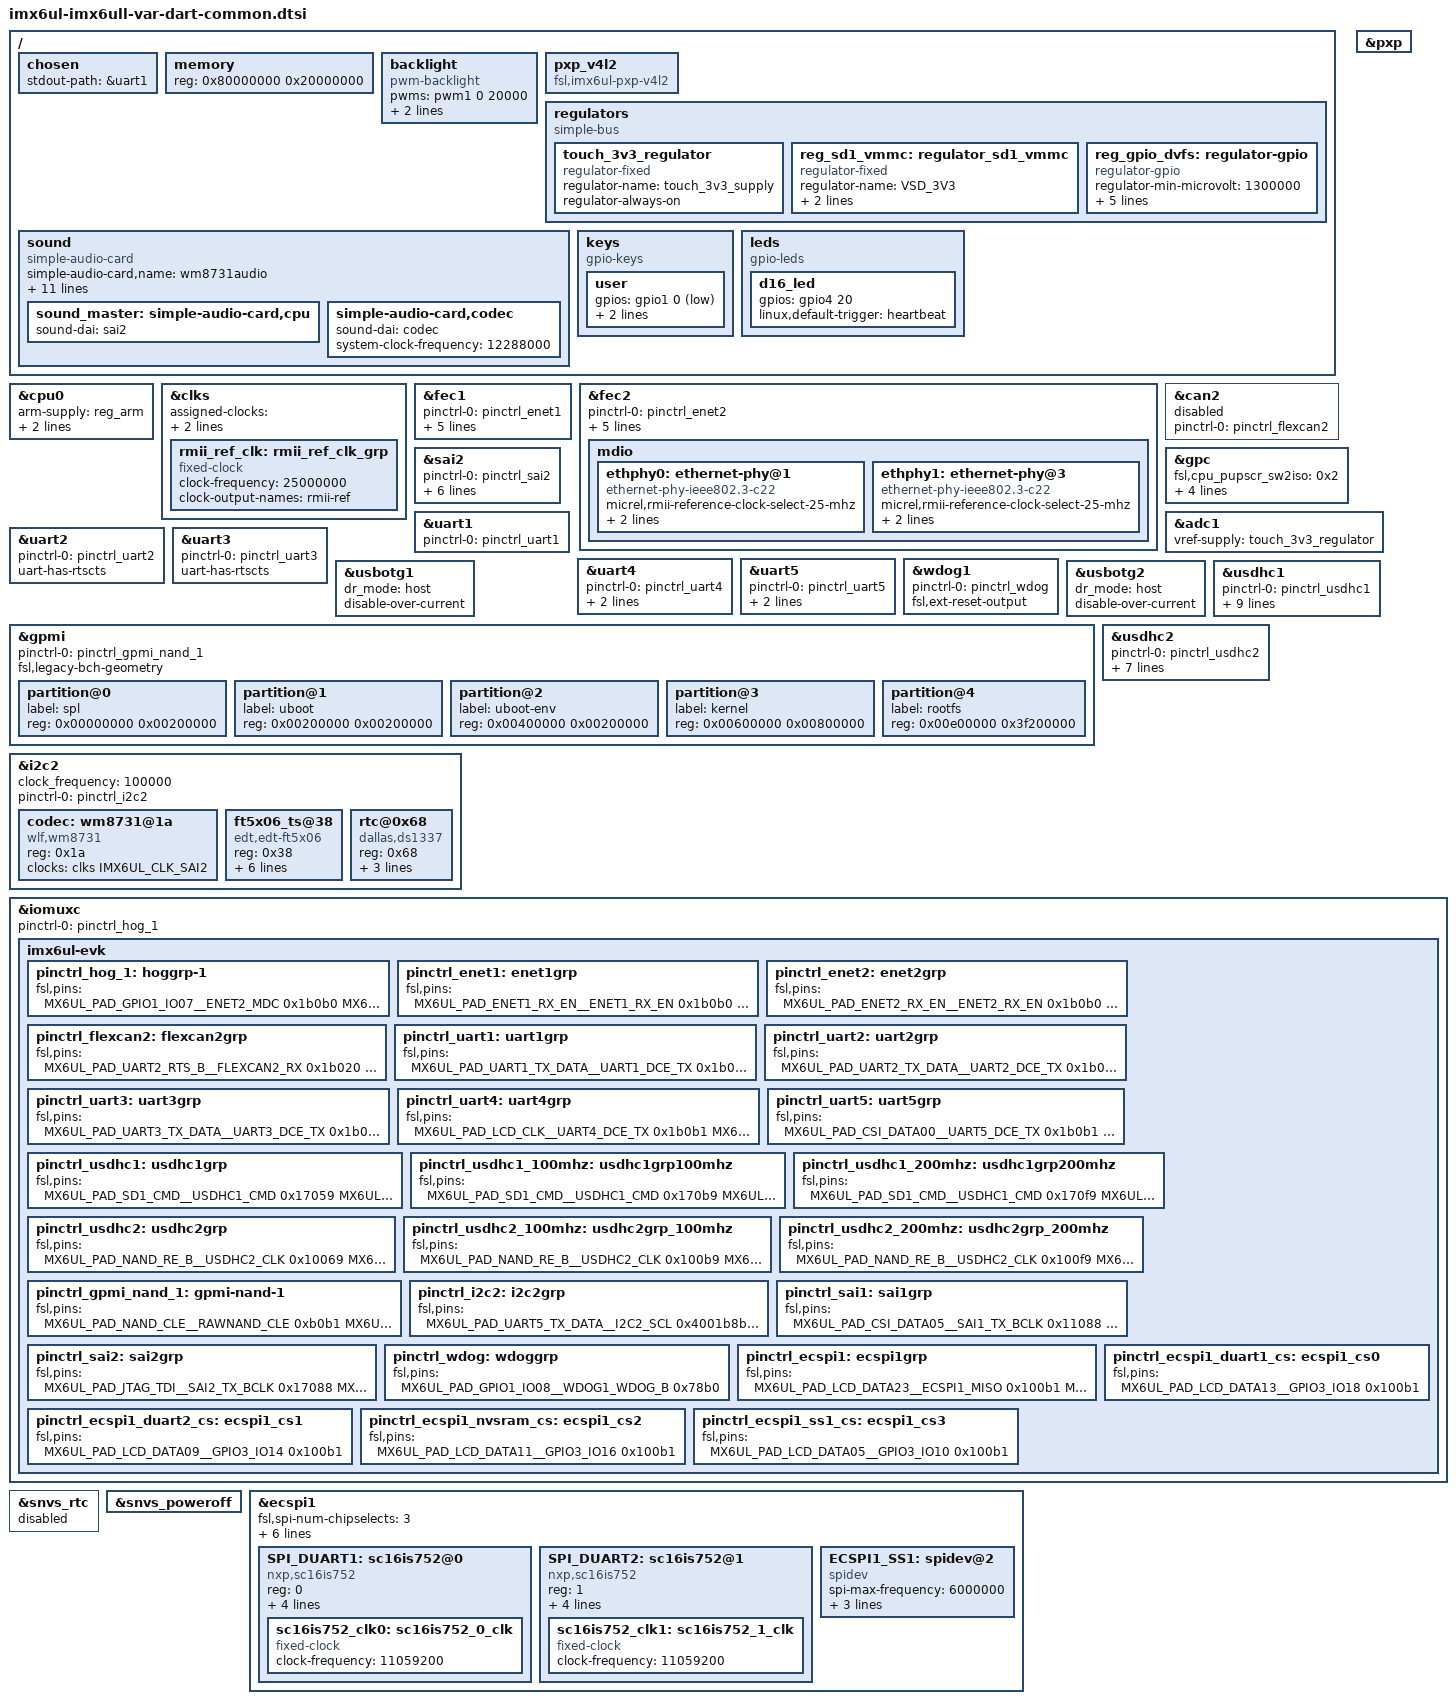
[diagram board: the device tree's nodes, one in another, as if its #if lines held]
/*
 * Copyright (C) 2015 Freescale Semiconductor, Inc.
 *
 * Copyright (C) 2015-2017 Variscite Ltd. - http://www.variscite.com
 *
 * This program is free software; you can redistribute it and/or modify
 * it under the terms of the GNU General Public License version 2 as
 * published by the Free Software Foundation.
 */
/* #define WIFI */
/* #define EMMC */
/* #define  NAND  */

/ {
	chosen {
		stdout-path = &uart1;
	};

	memory {
		reg = <0x80000000 0x20000000>;
	};

	backlight {
		compatible = "pwm-backlight";
		pwms = <&pwm1 0 20000>;
		brightness-levels = <0 4 8 16 32 64 128 255>;
		default-brightness-level = <6>;
		status = "okay";
	};

	pxp_v4l2 {
		compatible = "fsl,imx6ul-pxp-v4l2", "fsl,imx6sx-pxp-v4l2", "fsl,imx6sl-pxp-v4l2";
		status = "okay";
	};

	regulators {
		compatible = "simple-bus";
		#address-cells = <1>;
		#size-cells = <0>;

		touch_3v3_regulator: touch_3v3_regulator {
			compatible = "regulator-fixed";
			regulator-name = "touch_3v3_supply";
			regulator-always-on;
			status = "okay";
		};

#ifdef WIFI
		reg_sd1_vmmc: regulator_sd1_vmmc {
			compatible = "regulator-fixed";
			regulator-name = "VSD_3V3";
			regulator-min-microvolt = <3300000>;
			regulator-max-microvolt = <3300000>;
		};
#endif
		reg_gpio_dvfs: regulator-gpio {
			compatible = "regulator-gpio";
			regulator-min-microvolt = <1300000>;
			regulator-max-microvolt = <1400000>;
			regulator-name = "gpio_dvfs";
			regulator-type = "voltage";
			gpios = <&gpio4 13 GPIO_ACTIVE_HIGH>;
			states = <1300000 0x1 1400000 0x0>;
		};
	};

	sound {
		compatible = "simple-audio-card";
		simple-audio-card,name = "wm8731audio";
		simple-audio-card,widgets =
			"Headphone", "Headphone Jack",
			"Line", "Line Jack",
			"Microphone", "Mic Jack";
		simple-audio-card,routing =
			"Headphone Jack", "RHPOUT",
			"Headphone Jack", "LHPOUT",
			"LLINEIN", "Line Jack",
			"RLINEIN", "Line Jack",
			"MICIN", "Mic Bias",
			"Mic Bias", "Mic Jack";
		simple-audio-card,format = "i2s";
		simple-audio-card,bitclock-master = <&sound_master>;
		simple-audio-card,frame-master = <&sound_master>;
		/*simple-audio-card,bitclock-inversion;*/

		sound_master: simple-audio-card,cpu {
			sound-dai = <&sai2>;
		};

		simple-audio-card,codec {
			sound-dai = <&codec>;
			system-clock-frequency = <12288000>;
		};
	};

	keys {
		compatible = "gpio-keys";

		user {
			gpios = <&gpio1 0 GPIO_ACTIVE_LOW>;
			linux,code = <KEY_BACK>;
			gpio-key,wakeup;
		};
	};

	leds {
		compatible = "gpio-leds";

		d16_led {
			gpios = <&gpio4 20 0>;
			linux,default-trigger = "heartbeat";
		};
	};
};

&cpu0 {
	arm-supply = <&reg_arm>;
	soc-supply = <&reg_soc>;
	dc-supply = <&reg_gpio_dvfs>;
};

&clks {
	/* ref_clk for micrel ethernet phy */
	rmii_ref_clk: rmii_ref_clk_grp {
		compatible = "fixed-clock";
		#clock-cells = <0>;
		clock-frequency = <25000000>;
		clock-output-names = "rmii-ref";
	};
};

&clks {
	assigned-clocks = <&clks IMX6UL_CLK_PLL4_AUDIO_DIV>;
	assigned-clock-rates = <786432000>;
};

&fec1 {
	pinctrl-names = "default";
	pinctrl-0 = <&pinctrl_enet1>;
	phy-mode = "rmii";
	phy-reset-gpios=<&gpio5 0 1>;
	phy-reset-duration=<100>;
	phy-reset-on-resume;
	phy-handle = <&ethphy0>;
	status = "okay";
};

&fec2 {
	pinctrl-names = "default";
	pinctrl-0 = <&pinctrl_enet2>;
	phy-mode = "rmii";
	phy-handle = <&ethphy1>;
	phy-reset-gpios=<&gpio1 10 1>;
	phy-reset-duration=<100>;
	phy-reset-on-resume;
	status = "okay";
	mdio {
		#address-cells = <1>;
		#size-cells = <0>;

		ethphy0: ethernet-phy@1 {
			compatible = "ethernet-phy-ieee802.3-c22";
			micrel,rmii-reference-clock-select-25-mhz;
			clocks = <&rmii_ref_clk>;
			clock-names = "rmii-ref";
			reg = <1>;
		};

		ethphy1: ethernet-phy@3 {
			compatible = "ethernet-phy-ieee802.3-c22";
			micrel,rmii-reference-clock-select-25-mhz;
			clocks = <&rmii_ref_clk>;
			clock-names = "rmii-ref";
			reg = <3>;
		};
	};
};

&can2 {
	pinctrl-names = "default";
	pinctrl-0 = <&pinctrl_flexcan2>;
	status = "disabled";
};

&gpc {
	fsl,cpu_pupscr_sw2iso = <0x2>;
	fsl,cpu_pupscr_sw = <0x1>;
	fsl,cpu_pdnscr_iso2sw = <0x1>;
	fsl,cpu_pdnscr_iso = <0x1>;
	fsl,ldo-bypass = <0>; /* DCDC, ldo-enable */
};

&pxp {
	status = "okay";
};

&sai2 {
	pinctrl-names = "default";
	pinctrl-0 = <&pinctrl_sai2>;
	assigned-clocks = <&clks IMX6UL_CLK_SAI2_SEL>,
			  <&clks IMX6UL_CLK_SAI2>;
	assigned-clock-parents = <&clks IMX6UL_CLK_PLL4_AUDIO_DIV>;
	assigned-clock-rates = <0>, <12288000>;
	fsl,sai-mclk-direction-output;
	status = "okay";
};

&adc1 {
	vref-supply = <&touch_3v3_regulator>;
	status = "okay";
};

/* Console UART */
&uart1 {
	pinctrl-names = "default";
	pinctrl-0 = <&pinctrl_uart1>;
	status = "okay";
};

/* Bluetooth UART */
&uart2 {
	pinctrl-names = "default";
	pinctrl-0 = <&pinctrl_uart2>;
	uart-has-rtscts;
	status = "okay";
};

/* ttymxc2 UART */
&uart3 {
	pinctrl-names = "default";
	pinctrl-0 = <&pinctrl_uart3>;
	uart-has-rtscts;
	status = "okay";
};

/* ttymxc3 UART */
&uart4 {
	pinctrl-names = "default";
	pinctrl-0 = <&pinctrl_uart4>;
	dcd-gpios = <&gpio1 5 GPIO_ACTIVE_LOW>;
	fsl,uart-has-rtscts;
	status = "okay";
};

/* ttymxc4 UART */
&uart5 {
	pinctrl-names = "default";
	pinctrl-0 = <&pinctrl_uart5>;
	dcd-gpios = <&gpio5 1 GPIO_ACTIVE_LOW>;
	fsl,uart-has-rtscts;
	status = "okay";
};

&wdog1 {
	pinctrl-names = "default";
	pinctrl-0 = <&pinctrl_wdog>;
	fsl,ext-reset-output;
};

&usbotg1 {
	dr_mode = "host";
	disable-over-current;
	status = "okay";
};

&usbotg2 {
	dr_mode = "host";
	disable-over-current;
	status = "okay";
};

#ifdef WIFI
#ifdef WIFI_5G
/*  Wi-Fi/BT SD Card Slot Definition */
&usdhc1 {
	pinctrl-names = "default", "state_100mhz", "state_200mhz";
	pinctrl-0 = <&pinctrl_usdhc1>;
	pinctrl-1 = <&pinctrl_usdhc1_100mhz>;
	pinctrl-2 = <&pinctrl_usdhc1_200mhz>;
	assigned-clocks = <&clks IMX6UL_CLK_USDHC1_SEL>, <&clks IMX6UL_CLK_USDHC1>;
	assigned-clock-parents = <&clks IMX6UL_CLK_PLL2_PFD2>;
	assigned-clock-rates = <0>, <132000000>;
	fsl,tuning-step= <2>;
	vmmc-supply = <&reg_sd1_vmmc>;
	status = "okay";
};
#else
&usdhc1 {
	pinctrl-names = "default", "state_100mhz", "state_200mhz";
	pinctrl-0 = <&pinctrl_usdhc1>;
	pinctrl-1 = <&pinctrl_usdhc1_100mhz>;
	pinctrl-2 = <&pinctrl_usdhc1_200mhz>;
	no-1-8-v;
	keep-power-in-suspend;
	vmmc-supply = <&reg_sd1_vmmc>;
	non-removable;
	status = "okay";
};
#endif /* WIFI_5G */
#else
&usdhc1 {
	pinctrl-names = "default", "state_100mhz", "state_200mhz";
	pinctrl-0 = <&pinctrl_usdhc1>;
	pinctrl-1 = <&pinctrl_usdhc1_100mhz>;
	pinctrl-2 = <&pinctrl_usdhc1_200mhz>;
	no-1-8-v;
	keep-power-in-suspend;
	enable-sdio-wakeup;
	cd-gpios = <&gpio4 19 GPIO_ACTIVE_LOW>;
	status = "okay";
};
#endif

#ifdef NAND
&gpmi {
	pinctrl-names = "default";
	pinctrl-0 = <&pinctrl_gpmi_nand_1>;
	fsl,legacy-bch-geometry;
	status = "okay";

	partition@0 {
		label = "spl";
		reg = <0x00000000 0x00200000>;
	};

	partition@1 {
		label = "uboot";
		reg = <0x00200000 0x00200000>;
	};

	partition@2 {
		label = "uboot-env";
		reg = <0x00400000 0x00200000>;
	};

	partition@3 {
		label = "kernel";
		reg = <0x00600000 0x00800000>;
	};

	partition@4 {
		label = "rootfs";
		reg = <0x00e00000 0x3f200000>;
	};
};

&usdhc2 {
	status = "disabled";
};
#endif

#ifdef EMMC
&usdhc2 {
	pinctrl-names = "default", "state_100mhz", "state_200mhz";
	pinctrl-0 = <&pinctrl_usdhc2>;
	pinctrl-1 = <&pinctrl_usdhc2_100mhz>;
	pinctrl-2 = <&pinctrl_usdhc2_200mhz>;
	bus-width = <8>;
	no-1-8-v;
	non-removable;
	keep-power-in-suspend;
	enable-sdio-wakeup;
	status = "okay";
};
#endif

&i2c2 {
	clock_frequency = <100000>;
	pinctrl-names = "default";
	pinctrl-0 = <&pinctrl_i2c2>;
	status = "okay";

	codec: wm8731@1a {
		#sound-dai-cells = <0>;
		compatible = "wlf,wm8731";
		reg = <0x1a>;
		clocks = <&clks IMX6UL_CLK_SAI2>;
		clock-names = "mclk";
	};

	ft5x06_ts@38 {
		compatible = "edt,edt-ft5x06";
		reg = <0x38>;
		interrupt-parent = <&gpio3>;
		interrupts = <4 0>;
		touchscreen-size-x = <800>;
		touchscreen-size-y = <480>;
		touchscreen-inverted-x;
		touchscreen-inverted-y;
	};

	/* DS1337 RTC module */
	rtc@0x68 {
		compatible = "dallas,ds1337";
		reg = <0x68>;
		pinctrl-names = "default";
		pinctrl-0 = <&pinctrl_rtc>;
		interrupt-parent = <&gpio5>;
		interrupts = <7 IRQ_TYPE_EDGE_FALLING>;
	};
};

&iomuxc {
	pinctrl-names = "default";
	pinctrl-0 = <&pinctrl_hog_1>;
	imx6ul-evk {
		pinctrl_hog_1: hoggrp-1 {
			fsl,pins = <
				MX6UL_PAD_GPIO1_IO07__ENET2_MDC		0x1b0b0
				MX6UL_PAD_GPIO1_IO06__ENET2_MDIO	0x1b0b0
#ifdef WIFI
				MX6UL_PAD_GPIO1_IO03__REF_CLK_32K	0x03029	/* WLAN Slow Clock */
#endif
				/* gpios */
				MX6UL_PAD_SNVS_TAMPER5__GPIO5_IO05	0x5800A0 /* SCC_AB */
				MX6UL_PAD_SNVS_TAMPER3__GPIO5_IO03	0x5800A0 /* SCC_DC */
				MX6UL_PAD_LCD_DATA02__GPIO3_IO07	0x5800A0 /* SCC_CE */
				MX6UL_PAD_LCD_DATA16__GPIO3_IO21	0x5800A0 /* SCC_D4 */
				MX6UL_PAD_LCD_DATA18__GPIO3_IO23	0x5800A0 /* SCC_D6 */
				MX6UL_PAD_LCD_DATA17__GPIO3_IO22	0x5800A0 /* SCC_D5 */
				MX6UL_PAD_LCD_DATA14__GPIO3_IO19	0x5800A0 /* SCC_D2 */
				MX6UL_PAD_LCD_DATA12__GPIO3_IO17	0x5800A0 /* SCC_D1 */
				MX6UL_PAD_LCD_DATA08__GPIO3_IO13	0x5800A0 /* SCC_D0 */
				MX6UL_PAD_LCD_DATA04__GPIO3_IO09	0x5800A0 /* GPS_RESET */
				MX6UL_PAD_LCD_DATA19__GPIO3_IO24	0x5800A0 /* SCC_D7 */
				MX6UL_PAD_LCD_DATA15__GPIO3_IO20	0x5800A0 /* SCC_D3 */
				MX6UL_PAD_LCD_DATA01__GPIO3_IO06	0x5800A0 /* SCC_RD */
				MX6UL_PAD_LCD_DATA03__GPIO3_IO08	0x5800A0 /* SCC_WR */
				MX6UL_PAD_LCD_DATA00__GPIO3_IO05	0x5800A0 /* SCC_INTACK */
				MX6UL_PAD_LCD_DATA10__GPIO3_IO15	0x5800A0 /* SCC_DIR */
				MX6UL_PAD_LCD_RESET__GPIO3_IO04		0x5800A0 /* SCC_IEO */
				MX6UL_PAD_CSI_PIXCLK__GPIO4_IO18	0x5800A0 /* HOST_USB_PWR_SW */
				MX6UL_PAD_CSI_MCLK__GPIO4_IO17		0x5800A0 /* HOST_USB_OVCR */
				MX6UL_PAD_GPIO1_IO05__GPIO1_IO05	0x5800A0 /* SP1_DCD */
				MX6UL_PAD_SNVS_TAMPER7__GPIO5_IO07	0x5800A0 /* RTC_IRQ */
				MX6UL_PAD_SNVS_TAMPER8__GPIO5_IO08	0x5800A0 /* HOST_LINESYNC */
				MX6UL_PAD_SNVS_TAMPER9__GPIO5_IO09	0x5800A0 /* PCA9555_INT */
				MX6UL_PAD_UART4_TX_DATA__GPIO1_IO28	0x5800A0 /* SCC_INT */
				MX6UL_PAD_GPIO1_IO01__GPIO1_IO01	0x5800A0 /* ENGX_USB_OVRC */
				MX6UL_PAD_GPIO1_IO02__GPIO1_IO02	0x5800A0 /* SPI_DUART_RESET */
				MX6UL_PAD_GPIO1_IO04__GPIO1_IO04	0x5800A0 /* ENGX_USB_VBUSCTRL */
				MX6UL_PAD_GPIO1_IO00__GPIO1_IO00	0x5800A0 /* ADC0.0 */
				MX6UL_PAD_SNVS_TAMPER1__GPIO5_IO01	0x5800A0 /* SP2_DCD */
			>;
		};

		pinctrl_enet1: enet1grp {
			fsl,pins = <
				MX6UL_PAD_ENET1_RX_EN__ENET1_RX_EN	0x1b0b0
				MX6UL_PAD_ENET1_RX_ER__ENET1_RX_ER	0x1b0b0
				MX6UL_PAD_ENET1_RX_DATA0__ENET1_RDATA00	0x1b0b0
				MX6UL_PAD_ENET1_RX_DATA1__ENET1_RDATA01	0x1b0b0
				MX6UL_PAD_ENET1_TX_EN__ENET1_TX_EN	0x1b0b0
				MX6UL_PAD_ENET1_TX_DATA0__ENET1_TDATA00	0x1b0b0
				MX6UL_PAD_ENET1_TX_DATA1__ENET1_TDATA01	0x1b0b0
				MX6UL_PAD_ENET1_TX_CLK__ENET1_REF_CLK1	0x4001b031
			>;
		};

		pinctrl_enet2: enet2grp {
			fsl,pins = <
				MX6UL_PAD_ENET2_RX_EN__ENET2_RX_EN	0x1b0b0
				MX6UL_PAD_ENET2_RX_ER__ENET2_RX_ER	0x1b0b0
				MX6UL_PAD_ENET2_RX_DATA0__ENET2_RDATA00	0x1b0b0
				MX6UL_PAD_ENET2_RX_DATA1__ENET2_RDATA01	0x1b0b0
				MX6UL_PAD_ENET2_TX_EN__ENET2_TX_EN	0x1b0b0
				MX6UL_PAD_ENET2_TX_DATA0__ENET2_TDATA00	0x1b0b0
				MX6UL_PAD_ENET2_TX_DATA1__ENET2_TDATA01	0x1b0b0
				MX6UL_PAD_ENET2_TX_CLK__ENET2_REF_CLK2	0x4001b031
				MX6UL_PAD_JTAG_MOD__GPIO1_IO10		0x1b0b0
			>;
		};

		pinctrl_flexcan2: flexcan2grp{
			fsl,pins = <
				MX6UL_PAD_UART2_RTS_B__FLEXCAN2_RX	0x1b020
				MX6UL_PAD_UART2_CTS_B__FLEXCAN2_TX	0x1b020
			>;
		};

		pinctrl_uart1: uart1grp {
			fsl,pins = <
				MX6UL_PAD_UART1_TX_DATA__UART1_DCE_TX	0x1b0b1
				MX6UL_PAD_UART1_RX_DATA__UART1_DCE_RX	0x1b0b1
			>;
		};

		pinctrl_uart2: uart2grp {
			fsl,pins = <
				MX6UL_PAD_UART2_TX_DATA__UART2_DCE_TX	0x1b0b1
				MX6UL_PAD_UART2_RX_DATA__UART2_DCE_RX	0x1b0b1
				MX6UL_PAD_UART2_CTS_B__UART2_DCE_CTS	0x1b0b1
				MX6UL_PAD_UART2_RTS_B__UART2_DCE_RTS	0x1b0b1
			>;
		};

		pinctrl_uart3: uart3grp {
			fsl,pins = <
				MX6UL_PAD_UART3_TX_DATA__UART3_DCE_TX	0x1b0b1
				MX6UL_PAD_UART3_RX_DATA__UART3_DCE_RX	0x1b0b1
				MX6UL_PAD_UART3_CTS_B__UART3_DCE_CTS	0x1b0b1
				MX6UL_PAD_UART3_RTS_B__UART3_DCE_RTS	0x1b0b1
			>;
		};

		pinctrl_uart4: uart4grp {
			fsl,pins = <
				MX6UL_PAD_LCD_CLK__UART4_DCE_TX		0x1b0b1
				MX6UL_PAD_LCD_ENABLE__UART4_DCE_RX	0x1b0b1
				MX6UL_PAD_LCD_VSYNC__UART4_DCE_RTS	0x1b0b1
				MX6UL_PAD_LCD_HSYNC__UART4_DCE_CTS	0x1b0b1
			>;
		};

		pinctrl_uart5: uart5grp {
			fsl,pins = <
				MX6UL_PAD_CSI_DATA00__UART5_DCE_TX	0x1b0b1
				MX6UL_PAD_CSI_DATA01__UART5_DCE_RX	0x1b0b1
				MX6UL_PAD_CSI_DATA03__UART5_DCE_CTS	0x1b0b1
				MX6UL_PAD_CSI_DATA02__UART5_DCE_RTS	0x1b0b1
			>;
		};

		pinctrl_usdhc1: usdhc1grp {
			fsl,pins = <
				MX6UL_PAD_SD1_CMD__USDHC1_CMD		0x17059
				MX6UL_PAD_SD1_CLK__USDHC1_CLK		0x17059
				MX6UL_PAD_SD1_DATA0__USDHC1_DATA0	0x17059
				MX6UL_PAD_SD1_DATA1__USDHC1_DATA1	0x17059
				MX6UL_PAD_SD1_DATA2__USDHC1_DATA2	0x17059
				MX6UL_PAD_SD1_DATA3__USDHC1_DATA3	0x17059
				MX6UL_PAD_CSI_VSYNC__GPIO4_IO19		0x1b0b1	/* SD card detect */
			>;
		};

		pinctrl_usdhc1_100mhz: usdhc1grp100mhz {
			fsl,pins = <
				MX6UL_PAD_SD1_CMD__USDHC1_CMD		0x170b9
				MX6UL_PAD_SD1_CLK__USDHC1_CLK		0x100b9
				MX6UL_PAD_SD1_DATA0__USDHC1_DATA0	0x170b9
				MX6UL_PAD_SD1_DATA1__USDHC1_DATA1	0x170b9
				MX6UL_PAD_SD1_DATA2__USDHC1_DATA2	0x170b9
				MX6UL_PAD_SD1_DATA3__USDHC1_DATA3	0x170b9
				MX6UL_PAD_CSI_VSYNC__GPIO4_IO19		0x1b0b1	/* SD card detect */
			>;
		};

		pinctrl_usdhc1_200mhz: usdhc1grp200mhz {
			fsl,pins = <
				MX6UL_PAD_SD1_CMD__USDHC1_CMD		0x170f9
				MX6UL_PAD_SD1_CLK__USDHC1_CLK		0x100f9
				MX6UL_PAD_SD1_DATA0__USDHC1_DATA0	0x170f9
				MX6UL_PAD_SD1_DATA1__USDHC1_DATA1	0x170f9
				MX6UL_PAD_SD1_DATA2__USDHC1_DATA2	0x170f9
				MX6UL_PAD_SD1_DATA3__USDHC1_DATA3	0x170f9
				MX6UL_PAD_CSI_VSYNC__GPIO4_IO19		0x1b0b1	/* SD card detect */
			>;
		};
#ifdef EMMC
		pinctrl_usdhc2: usdhc2grp {
			fsl,pins = <
				MX6UL_PAD_NAND_RE_B__USDHC2_CLK		0x10069
				MX6UL_PAD_NAND_WE_B__USDHC2_CMD		0x17059
				MX6UL_PAD_NAND_DATA00__USDHC2_DATA0	0x17059
				MX6UL_PAD_NAND_DATA01__USDHC2_DATA1	0x17059
				MX6UL_PAD_NAND_DATA02__USDHC2_DATA2	0x17059
				MX6UL_PAD_NAND_DATA03__USDHC2_DATA3	0x17059
				MX6UL_PAD_NAND_DATA04__USDHC2_DATA4	0x17059
				MX6UL_PAD_NAND_DATA05__USDHC2_DATA5	0x17059
				MX6UL_PAD_NAND_DATA06__USDHC2_DATA6	0x17059
				MX6UL_PAD_NAND_DATA07__USDHC2_DATA7	0x17059
			>;
		};

		pinctrl_usdhc2_100mhz: usdhc2grp_100mhz {
			fsl,pins = <
				MX6UL_PAD_NAND_RE_B__USDHC2_CLK		0x100b9
				MX6UL_PAD_NAND_WE_B__USDHC2_CMD		0x170b9
				MX6UL_PAD_NAND_DATA00__USDHC2_DATA0	0x170b9
				MX6UL_PAD_NAND_DATA01__USDHC2_DATA1	0x170b9
				MX6UL_PAD_NAND_DATA02__USDHC2_DATA2	0x170b9
				MX6UL_PAD_NAND_DATA03__USDHC2_DATA3	0x170b9
				MX6UL_PAD_NAND_DATA04__USDHC2_DATA4	0x170b9
				MX6UL_PAD_NAND_DATA05__USDHC2_DATA5	0x170b9
				MX6UL_PAD_NAND_DATA06__USDHC2_DATA6	0x170b9
				MX6UL_PAD_NAND_DATA07__USDHC2_DATA7	0x170b9
			>;
		};

		pinctrl_usdhc2_200mhz: usdhc2grp_200mhz {
			fsl,pins = <
				MX6UL_PAD_NAND_RE_B__USDHC2_CLK		0x100f9
				MX6UL_PAD_NAND_WE_B__USDHC2_CMD		0x170f9
				MX6UL_PAD_NAND_DATA00__USDHC2_DATA0	0x170f9
				MX6UL_PAD_NAND_DATA01__USDHC2_DATA1	0x170f9
				MX6UL_PAD_NAND_DATA02__USDHC2_DATA2	0x170f9
				MX6UL_PAD_NAND_DATA03__USDHC2_DATA3	0x170f9
				MX6UL_PAD_NAND_DATA04__USDHC2_DATA4	0x170f9
				MX6UL_PAD_NAND_DATA05__USDHC2_DATA5	0x170f9
				MX6UL_PAD_NAND_DATA06__USDHC2_DATA6	0x170f9
				MX6UL_PAD_NAND_DATA07__USDHC2_DATA7	0x170f9
			>;
		};
#endif
#ifdef NAND
		pinctrl_gpmi_nand_1: gpmi-nand-1 {
			fsl,pins = <
				MX6UL_PAD_NAND_CLE__RAWNAND_CLE		0xb0b1
				MX6UL_PAD_NAND_ALE__RAWNAND_ALE		0xb0b1
				MX6UL_PAD_NAND_WP_B__RAWNAND_WP_B	0xb0b1
				MX6UL_PAD_NAND_READY_B__RAWNAND_READY_B	0xb000
				MX6UL_PAD_NAND_CE0_B__RAWNAND_CE0_B	0xb0b1
				MX6UL_PAD_NAND_RE_B__RAWNAND_RE_B	0xb0b1
				MX6UL_PAD_NAND_WE_B__RAWNAND_WE_B	0xb0b1
				MX6UL_PAD_NAND_DATA00__RAWNAND_DATA00	0xb0b1
				MX6UL_PAD_NAND_DATA01__RAWNAND_DATA01	0xb0b1
				MX6UL_PAD_NAND_DATA02__RAWNAND_DATA02	0xb0b1
				MX6UL_PAD_NAND_DATA03__RAWNAND_DATA03	0xb0b1
				MX6UL_PAD_NAND_DATA04__RAWNAND_DATA04	0xb0b1
				MX6UL_PAD_NAND_DATA05__RAWNAND_DATA05	0xb0b1
				MX6UL_PAD_NAND_DATA06__RAWNAND_DATA06	0xb0b1
				MX6UL_PAD_NAND_DATA07__RAWNAND_DATA07	0xb0b1
			>;
		};
#endif

		pinctrl_i2c2: i2c2grp {
			fsl,pins = <
				MX6UL_PAD_UART5_TX_DATA__I2C2_SCL	0x4001b8b0
				MX6UL_PAD_UART5_RX_DATA__I2C2_SDA	0x4001b8b0
			>;
		};

		pinctrl_sai1: sai1grp {
			fsl,pins = <
				MX6UL_PAD_CSI_DATA05__SAI1_TX_BCLK	0x11088
				MX6UL_PAD_CSI_DATA04__SAI1_TX_SYNC	0x17088
				MX6UL_PAD_CSI_DATA06__SAI1_RX_DATA	0x11088
				MX6UL_PAD_CSI_DATA07__SAI1_TX_DATA	0x11088
			>;
		};

		pinctrl_sai2: sai2grp {
			fsl,pins = <
				MX6UL_PAD_JTAG_TDI__SAI2_TX_BCLK	0x17088
				MX6UL_PAD_JTAG_TDO__SAI2_TX_SYNC	0x17088
				MX6UL_PAD_JTAG_TRST_B__SAI2_TX_DATA	0x11088
				MX6UL_PAD_JTAG_TCK__SAI2_RX_DATA	0x11088
				MX6UL_PAD_JTAG_TMS__SAI2_MCLK		0x17088
			>;
		};

		pinctrl_wdog: wdoggrp {
			fsl,pins = <
				MX6UL_PAD_GPIO1_IO08__WDOG1_WDOG_B	0x78b0
			>;
		};

		pinctrl_ecspi1: ecspi1grp {
			fsl,pins = <
				MX6UL_PAD_LCD_DATA23__ECSPI1_MISO	0x100b1
				MX6UL_PAD_LCD_DATA22__ECSPI1_MOSI	0x100b1
				MX6UL_PAD_LCD_DATA20__ECSPI1_SCLK	0x100b1
			>;
		};

		pinctrl_ecspi1_duart1_cs: ecspi1_cs0 {
			fsl,pins = <
				MX6UL_PAD_LCD_DATA13__GPIO3_IO18	0x100b1 /* SPI_DUART1_CS */
			>;
		};

		pinctrl_ecspi1_duart2_cs: ecspi1_cs1 {
			fsl,pins = <
				MX6UL_PAD_LCD_DATA09__GPIO3_IO14	0x100b1 /* SPI_DUART2_CS */
			>;
		};

		pinctrl_ecspi1_nvsram_cs: ecspi1_cs2 {
			fsl,pins = <
				MX6UL_PAD_LCD_DATA11__GPIO3_IO16	0x100b1 /* NVSRAM_CS */
			>;
		};

		pinctrl_ecspi1_ss1_cs: ecspi1_cs3 {
			fsl,pins = <
				MX6UL_PAD_LCD_DATA05__GPIO3_IO10	0x100b1 /* ECSPI1_SS1 */
			>;
		};
	};
};

&snvs_rtc {
	status = "disabled";
};

&snvs_poweroff {
	status = "okay";
};

&ecspi1 {
	fsl,spi-num-chipselects = <3>;
	cs-gpios =	<&gpio3 18 1>,
			<&gpio3 14 1>,
			/*
			<&gpio3 16 1>,
			*/
			<&gpio3 10 1>;
	pinctrl-names = "default";
	pinctrl-0 = <
		&pinctrl_ecspi1
		&pinctrl_ecspi1_duart1_cs
		&pinctrl_ecspi1_duart2_cs
		/*
		&pinctrl_ecspi1_nvsram_cs
		*/
		&pinctrl_ecspi1_ss1_cs
		>;
	status = "okay";

	SPI_DUART1: sc16is752@0 {
		compatible = "nxp,sc16is752";
		reg = <0>;
		clocks = <&sc16is752_clk0>;
		interrupt-parent = <&gpio1>;
		interrupts = <9 IRQ_TYPE_EDGE_FALLING>;
		spi-max-frequency = <6000000>;
		/*
		gpio-controller;
		#gpio-cells = <2>;
		*/
		sc16is752_clk0: sc16is752_0_clk {
			compatible = "fixed-clock";
			#clock-cells = <0>;
			clock-frequency = <11059200>;
		};
	};

	SPI_DUART2: sc16is752@1 {
		compatible = "nxp,sc16is752";
		reg = <1>;
		clocks = <&sc16is752_clk1>;
		interrupt-parent = <&gpio4>;
		interrupts = <20 IRQ_TYPE_EDGE_FALLING>;
		spi-max-frequency = <6000000>;
		/*
		gpio-controller;
		#gpio-cells = <2>;
		*/
		sc16is752_clk1: sc16is752_1_clk {
			compatible = "fixed-clock";
			#clock-cells = <0>;
			clock-frequency = <11059200>;
		};
	};

/*
	NVSRSM: spi_sram@2 {
		#address-cells = <1>;
		#size-cells = <1>;
		compatible = "microchip,mchp23lcv1024";
		reg = <2>;
		spi-max-frequency = <6000000>;
	};
*/

	ECSPI1_SS1: spidev@2 {
		compatible = "spidev";
		spi-max-frequency = <6000000>;
		reg = <2>;
		interrupt-parent = <&gpio1>;
		interrupts = <29 IRQ_TYPE_EDGE_FALLING>;
	};
};
